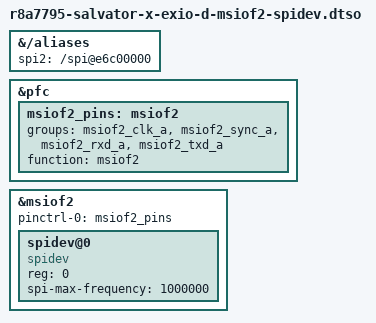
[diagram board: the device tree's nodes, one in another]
/*
 * Device Tree Overlay for MSIOF2 and spidev on r8a7795/salvator-x EXIO D
 *
 * Copyright (C) 2015 Glider bvba
 *
 * This file is licensed under the terms of the GNU General Public License
 * version 2.  This program is licensed "as is" without any warranty of any
 * kind, whether express or implied.
 *
 * Pinout:
 *   - 3V3  = EXIO B(!) pin 39, 40, 41, 42
 *
 *   - GND  = EXIO D pin 3, 4, 7, 8, 12, 17, 18
 *   - CS#  = EXIO D pin 27
 *   - SCK  = EXIO D pin 25
 *   - MOSI = EXIO D pin 21
 *   - MISO = EXIO D pin 23
 */

/dts-v1/ /plugin/;

/ {
	fragment-aliases {
		target-path = "/aliases";

		__overlay__ {
			/* spi2 = &msiof2; */
			spi2 = "/spi@e6c00000";
		};
	};

	fragment-pfc {
		target = <&pfc>;

		__overlay__ {
			msiof2_pins: msiof2 {
				groups = "msiof2_clk_a", "msiof2_sync_a",
					 "msiof2_rxd_a", "msiof2_txd_a";
				function = "msiof2";
			};
		};
	};

	fragment-msiof2 {
		target = <&msiof2>;

		__overlay__ {
			pinctrl-0 = <&msiof2_pins>;
			pinctrl-names = "default";

			#address-cells = <1>;
			#size-cells = <0>;
			status = "okay";

			spidev@0 {
				compatible = "spidev";
				reg = <0>;
				spi-max-frequency = <1000000>;
			};
		};
	};
};
